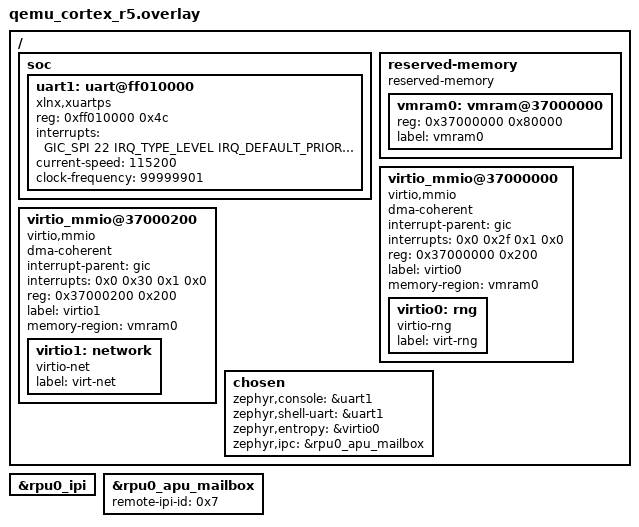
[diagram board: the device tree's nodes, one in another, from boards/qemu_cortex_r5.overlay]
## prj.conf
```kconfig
CONFIG_ASSERT=y
CONFIG_VIRTIO=y
CONFIG_VIRTIO_MMIO=y
CONFIG_VIRTIO_NETWORK=y
CONFIG_VIRTIO_RNG=y
CONFIG_ENTROPY_GENERATOR=y

CONFIG_EARLY_CONSOLE=y
CONFIG_SERIAL_INIT_PRIORITY=45
CONFIG_CONSOLE_INIT_PRIORITY=46

CONFIG_SHELL=y
CONFIG_NET_SHELL=y

CONFIG_NET_L2_ETHERNET=y
CONFIG_NET_DRIVERS=y
CONFIG_NETWORKING=y
CONFIG_NET_IPV6=n
CONFIG_NET_IPV4=y
CONFIG_NET_CONFIG_NEED_IPV4=y
CONFIG_NET_DHCPV4=y

CONFIG_COMPILER_OPT=" -DHVL_VIRTIO"
CONFIG_HAVE_CUSTOM_LINKER_SCRIPT=y
CONFIG_CUSTOM_LINKER_SCRIPT="linker_r5_hvl.ld"

CONFIG_OPENAMP=y
CONFIG_LIBMETAL=y
CONFIG_HEAP_MEM_POOL_SIZE=131072

CONFIG_IPM=y
CONFIG_XLNX_IPI_PREKERNEL_INIT=y
CONFIG_XLNX_IPI_INIT_PRIORITY=49
```

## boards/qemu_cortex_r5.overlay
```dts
/{

	soc {
		uart1: uart@ff010000 {
			compatible = "xlnx,xuartps";
			reg = <0xff010000 0x4c>;
			status = "disabled";
			interrupts = <GIC_SPI 22 IRQ_TYPE_LEVEL
					IRQ_DEFAULT_PRIORITY>;
			interrupt-names = "irq_1";
		};
	};
	reserved-memory {
		compatible = "reserved-memory";
		#address-cells = <1>;
		#size-cells = <1>;
		status = "okay";
		ranges;

		vmram0: vmram@37000000 {
			status = "okay";
			reg = < 0x37000000 0x80000 >;
			device_type = "memory";
			label = "vmram0";
		};
	};
	virtio_mmio@37000000 {
		dma-coherent;
		interrupt-parent = < &gic >;
		interrupts = < 0x0 0x2f 0x1 0x0 >;
		reg = < 0x37000000 0x200 >;
		compatible = "virtio,mmio";
		status = "okay";
		label = "virtio0";
		memory-region = < &vmram0 >;
		virtio0: rng {
			label = "virt-rng";
			compatible = "virtio-rng";
		};
	};
	virtio_mmio@37000200 {
		dma-coherent;
		interrupt-parent = < &gic >;
		interrupts = < 0x0 0x30 0x1 0x0 >;
		reg = < 0x37000200 0x200 >;
		compatible = "virtio,mmio";
		status = "okay";
		label = "virtio1";
		memory-region = < &vmram0 >;
		virtio1: network {
			label = "virt-net";
			compatible = "virtio-net";
		};
	};
	chosen {
		zephyr,console = &uart1;
		zephyr,shell-uart = &uart1;
		zephyr,entropy = &virtio0;
		zephyr,ipc = &rpu0_apu_mailbox;
	};
};
&rpu0_ipi {
	status = "okay";
};

&rpu0_apu_mailbox {
	remote-ipi-id = < 0x7 >;
	status = "okay";
};

&uart1 {
	status = "okay";
	current-speed = <115200>;
	clock-frequency = <99999901>;
};

/delete-node/ &uart0;
/delete-node/ &gem0;
/delete-node/ &gem1;
/delete-node/ &gem2;
/delete-node/ &gem3;
```

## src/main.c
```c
/*
 * Copyright (c) 2012-2024 Wind River Systems, Inc.
 *
 * SPDX-License-Identifier: Apache-2.0
 */

#include <zephyr/kernel.h>
#include <zephyr/sys/printk.h>
#include <zephyr/init.h>
#include <zephyr/net/net_if.h>
#include <zephyr/net/net_core.h>
#include <zephyr/net/net_ip.h>
#include <zephyr/net/net_mgmt.h>
#include <zephyr/drivers/entropy.h>

#define BUFFER_LENGTH 10
#define RECHECK_RANDOM_ENTROPY 0x10

extern char *net_sprint_addr(sa_family_t af, const void *addr);

#ifdef CONFIG_ENTROPY_GENERATOR
static int random_entropy(const struct device *dev, char *buffer, char num)
{
	int ret, i;
	int count = 0;

	(void)memset(buffer, num, BUFFER_LENGTH);

	/* The BUFFER_LENGTH-1 is used so the driver will not
	 * write the last byte of the buffer. If that last
	 * byte is not 0 on return it means the driver wrote
	 * outside the passed buffer, and that should never
	 * happen.
	 */
	ret = entropy_get_entropy(dev, buffer, BUFFER_LENGTH - 1);
	if (ret) {
		printk("Error: entropy_get_entropy failed: %d\n", ret);
		return -1;
	}

	if (buffer[BUFFER_LENGTH - 1] != num) {
		printk("Error: entropy_get_entropy buffer overflow\n");
		return -1;
	}

	for (i = 0; i < BUFFER_LENGTH - 1; i++) {
		printk("  0x%02x\n", buffer[i]);
		if (buffer[i] == num) {
			count++;
		}
	}

	if (count >= 2) {
		return RECHECK_RANDOM_ENTROPY;
	} else {
		return 0;
	}
}

/*
 * Function invokes the get_entropy callback in driver
 * to get the random data and fill to passed buffer
 */
static int get_entropy(void)
{
	const struct device *const dev = DEVICE_DT_GET(DT_CHOSEN(zephyr_entropy));
	uint8_t buffer[BUFFER_LENGTH] = { 0 };
	int ret;

	if (!device_is_ready(dev)) {
		printk("error: random device not ready\n");
		return -1;
	}

	printk("random device is %p, name is %s\n",
		 dev, dev->name);

	ret = random_entropy(dev, buffer, 0);

	/* Check whether 20% or more of buffer still filled with default
	 * value(0), if yes then recheck again by filling nonzero value(0xa5)
	 * to buffer. Recheck random_entropy and verify whether 20% or more
	 * of buffer filled with value(0xa5) or not.
	 */
	if (ret == RECHECK_RANDOM_ENTROPY) {
		ret = random_entropy(dev, buffer, 0xa5);
		if (ret == RECHECK_RANDOM_ENTROPY) {
			return -1;
		} else {
			return ret;
		}
	}
	return ret;
}
#endif

extern uint32_t __shmem0_pool_start;
extern uint32_t __shmem0_end;

void virtio_mmio_hvl_wait(uint32_t usec)
{
	k_busy_wait(usec);
}

int main(void)
{
	printk("Board: %s\n", CONFIG_BOARD);

#ifdef CONFIG_ENTROPY_GENERATOR
	//rng
	printk("%s:%d - get_entropy test %s\n", __FUNCTION__, __LINE__,
		(get_entropy() != 0) ? "failed" : "passed");
#endif

#ifdef CONFIG_NETWORKING
	//net
	struct net_if *iface;

	iface = net_if_get_default();

	struct in_addr my_addr2 = { { { 192, 168, 200, 2 } } };
	struct in_addr my_mask2 = { { { 255, 255, 255, 0 } } };
	struct net_if_addr *ifaddr;
	ifaddr = net_if_ipv4_addr_add(iface, &my_addr2, NET_ADDR_MANUAL, 0);
	if (!ifaddr) {
		printk("Cannot add IPv4 address %s\n", net_sprint_addr(AF_INET, &my_addr2));
		return -1;
    }
	net_if_ipv4_set_netmask_by_addr(iface, &my_addr2, &my_mask2);

	//ifaddr->addr_state = NET_ADDR_PREFERRED;
	net_if_up(iface);
#endif

	return 0;
}
```

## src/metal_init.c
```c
/*
 * Copyright (c) 2012-2024 Wind River Systems, Inc.
 *
 * SPDX-License-Identifier: Apache-2.0
 */

#include <zephyr/kernel.h>
#include <zephyr/sys/printk.h>
#include <zephyr/init.h>
#include <zephyr/net/net_if.h>
#include <zephyr/net/net_core.h>
#include <zephyr/net/net_ip.h>
#include <zephyr/net/net_mgmt.h>
#include <zephyr/drivers/entropy.h>
#include <metal/device.h>

int init_metal()
{
	int32_t err;
	struct metal_init_params metal_params = METAL_INIT_DEFAULTS;
	metal_params.log_level = METAL_LOG_DEBUG;

	err = metal_init(&metal_params);
	if (err) {
		metal_log(METAL_LOG_ERROR, "metal_init: failed - error code %d\n", err);
		return -ENODEV;
	}

	return 0;
}
SYS_INIT(init_metal, PRE_KERNEL_1, 49);
```

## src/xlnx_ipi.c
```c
/*
 * Copyright (c) 2021-2024 Wind River Systems, Inc.
 *
 * SPDX-License-Identifier: Apache-2.0
 *
 */

#include <zephyr/drivers/ipm.h>
#include <zephyr/logging/log.h>
#include <openamp/virtio_mmio.h>
#ifdef HVL_VIRTIO
#include <openamp/virtio_mmio_hvl.h>
#endif

LOG_MODULE_REGISTER(xlnx_ipi, LOG_LEVEL_DBG);

static const struct device *const ipm_handle =
	DEVICE_DT_GET(DT_CHOSEN(zephyr_ipc));

static void platform_ipm_callback(const struct device *dev, void *context,
				  uint32_t id, volatile void *data)
{
#ifdef HVL_VIRTIO
    virtio_mmio_hvl_cb_run();
#endif
}

int platform_init() {
	int status;

	if (!device_is_ready(ipm_handle)) {
		LOG_ERR("%s:%d - IPM device is not ready\n", __FUNCTION__, __LINE__);
		return -1;
	}

	ipm_register_callback(ipm_handle, platform_ipm_callback, NULL);
	status = ipm_set_enabled(ipm_handle, 1);
	if (status) {
		LOG_ERR("%s:%d - ipm_set_enabled failed\n", __FUNCTION__, __LINE__);
		return -1;
	}

	return 0;
}

void virtio_mmio_hvl_ipi(void *param) {

    (void)param;

	ipm_send(ipm_handle, 0, 7, NULL, 0);
}


int init_ipm() {
	int ret = platform_init();
	if (ret) {
		LOG_ERR("%s:%d - failed to initialize platform\n", __FUNCTION__, __LINE__);
		ret = -1;
	} else {
		LOG_DBG("%s:%d - platform initialized\n", __FUNCTION__, __LINE__);
	}

    return ret;
}

SYS_INIT(init_ipm, PRE_KERNEL_1, 49);
```
